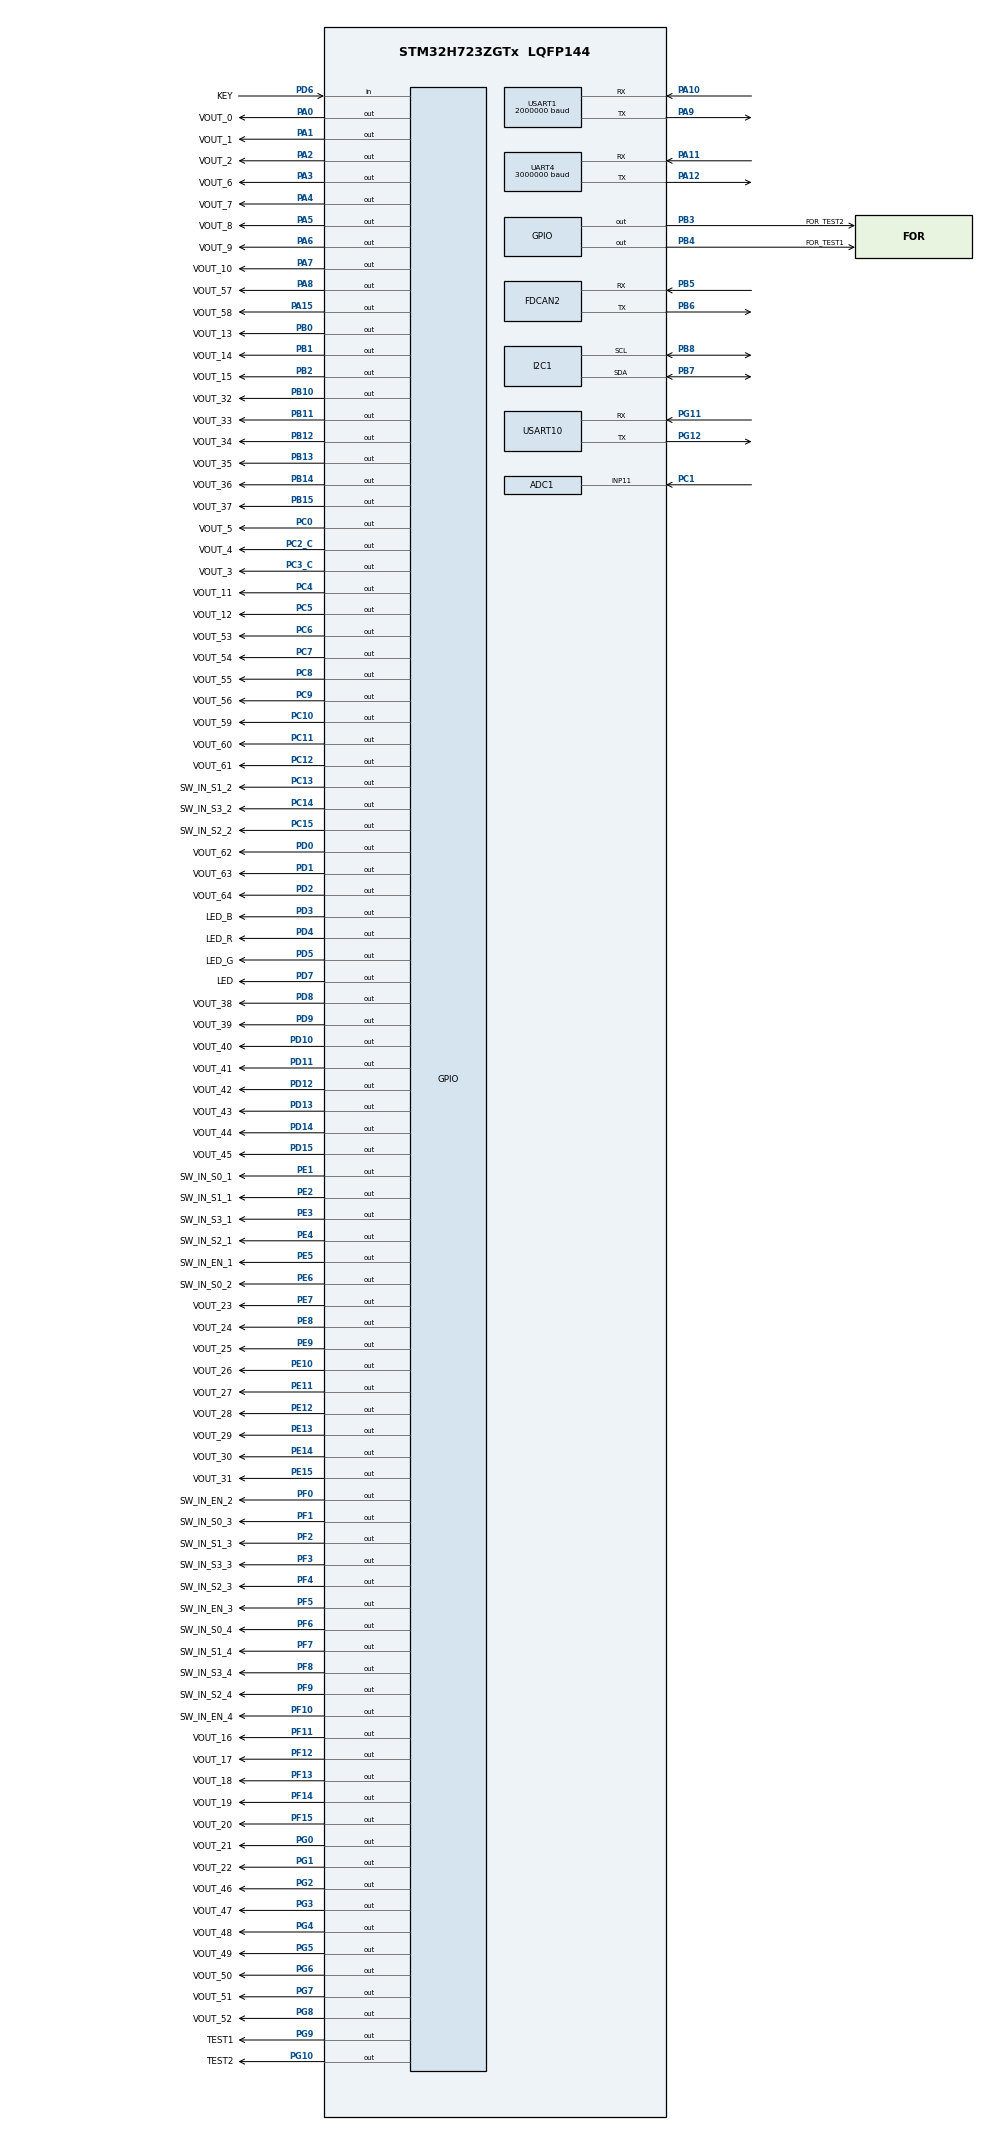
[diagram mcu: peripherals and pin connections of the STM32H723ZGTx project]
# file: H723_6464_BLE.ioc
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ADC1.Channel-0\#ChannelRegularConversion=ADC_CHANNEL_11
ADC1.ContinuousConvMode=ENABLE
ADC1.ConversionDataManagement=ADC_CONVERSIONDATA_DMA_CIRCULAR
ADC1.NbrOfConversionFlag=1
ADC1.OffsetNumber-0\#ChannelRegularConversion=ADC_OFFSET_NONE
ADC1.OffsetSignedSaturation-0\#ChannelRegularConversion=DISABLE
ADC1.Rank-0\#ChannelRegularConversion=1
ADC1.Resolution=ADC_RESOLUTION_10B
ADC1.SamplingTime-0\#ChannelRegularConversion=ADC_SAMPLETIME_1CYCLE_5
ADC1.master=1
CORTEX_M7.AccessPermission_S-Cortex_Memory_Protection_Unit_Region1_Settings_S=MPU_REGION_FULL_ACCESS
CORTEX_M7.BaseAddress_S-Cortex_Memory_Protection_Unit_Region1_Settings_S=0x30000000
CORTEX_M7.CPU_DCache=Enabled
CORTEX_M7.CPU_ICache=Enabled
CORTEX_M7.DisableExec_S-Cortex_Memory_Protection_Unit_Region1_Settings_S=MPU_INSTRUCTION_ACCESS_DISABLE
CORTEX_M7.Enable_S-Cortex_Memory_Protection_Unit_Region1_Settings_S=MPU_REGION_ENABLE
CORTEX_M7.IsBufferable_S-Cortex_Memory_Protection_Unit_Region1_Settings_S=MPU_ACCESS_BUFFERABLE
CORTEX_M7.IsShareable_S-Cortex_Memory_Protection_Unit_Region1_Settings_S=MPU_ACCESS_SHAREABLE
CORTEX_M7.Size_S-Cortex_Memory_Protection_Unit_Region1_Settings_S=MPU_REGION_SIZE_64KB
CORTEX_M7.default_mode_Activation=1
Dma.ADC1.2.Direction=DMA_PERIPH_TO_MEMORY
Dma.ADC1.2.EventEnable=DISABLE
Dma.ADC1.2.FIFOMode=DMA_FIFOMODE_DISABLE
Dma.ADC1.2.Instance=DMA1_Stream2
Dma.ADC1.2.MemDataAlignment=DMA_MDATAALIGN_HALFWORD
Dma.ADC1.2.MemInc=DMA_MINC_ENABLE
Dma.ADC1.2.Mode=DMA_CIRCULAR
Dma.ADC1.2.PeriphDataAlignment=DMA_PDATAALIGN_HALFWORD
Dma.ADC1.2.PeriphInc=DMA_PINC_DISABLE
Dma.ADC1.2.Polarity=HAL_DMAMUX_REQ_GEN_RISING
Dma.ADC1.2.Priority=DMA_PRIORITY_MEDIUM
Dma.ADC1.2.RequestNumber=1
Dma.ADC1.2.SignalID=NONE
Dma.ADC1.2.SyncEnable=DISABLE
Dma.ADC1.2.SyncPolarity=HAL_DMAMUX_SYNC_NO_EVENT
Dma.ADC1.2.SyncRequestNumber=1
Dma.ADC1.2.SyncSignalID=NONE
Dma.Request0=USART1_RX
Dma.Request1=USART1_TX
Dma.Request2=ADC1
Dma.Request3=UART4_TX
Dma.Request4=UART4_RX
Dma.UART4_RX.4.Direction=DMA_PERIPH_TO_MEMORY
Dma.UART4_RX.4.EventEnable=DISABLE
Dma.UART4_RX.4.FIFOMode=DMA_FIFOMODE_DISABLE
Dma.UART4_RX.4.Instance=DMA1_Stream3
Dma.UART4_RX.4.MemDataAlignment=DMA_MDATAALIGN_BYTE
Dma.UART4_RX.4.MemInc=DMA_MINC_ENABLE
Dma.UART4_RX.4.Mode=DMA_NORMAL
Dma.UART4_RX.4.PeriphDataAlignment=DMA_PDATAALIGN_BYTE
Dma.UART4_RX.4.PeriphInc=DMA_PINC_DISABLE
Dma.UART4_RX.4.Polarity=HAL_DMAMUX_REQ_GEN_RISING
Dma.UART4_RX.4.Priority=DMA_PRIORITY_VERY_HIGH
Dma.UART4_RX.4.RequestNumber=1
Dma.UART4_RX.4.SignalID=NONE
Dma.UART4_RX.4.SyncEnable=DISABLE
Dma.UART4_RX.4.SyncPolarity=HAL_DMAMUX_SYNC_NO_EVENT
Dma.UART4_RX.4.SyncRequestNumber=1
Dma.UART4_RX.4.SyncSignalID=NONE
Dma.UART4_TX.3.Direction=DMA_MEMORY_TO_PERIPH
Dma.UART4_TX.3.EventEnable=DISABLE
Dma.UART4_TX.3.FIFOMode=DMA_FIFOMODE_DISABLE
Dma.UART4_TX.3.Instance=DMA1_Stream4
Dma.UART4_TX.3.MemDataAlignment=DMA_MDATAALIGN_BYTE
Dma.UART4_TX.3.MemInc=DMA_MINC_ENABLE
Dma.UART4_TX.3.Mode=DMA_NORMAL
Dma.UART4_TX.3.PeriphDataAlignment=DMA_PDATAALIGN_BYTE
Dma.UART4_TX.3.PeriphInc=DMA_PINC_DISABLE
Dma.UART4_TX.3.Polarity=HAL_DMAMUX_REQ_GEN_RISING
Dma.UART4_TX.3.Priority=DMA_PRIORITY_LOW
Dma.UART4_TX.3.RequestNumber=1
Dma.UART4_TX.3.SignalID=NONE
Dma.UART4_TX.3.SyncEnable=DISABLE
Dma.UART4_TX.3.SyncPolarity=HAL_DMAMUX_SYNC_NO_EVENT
Dma.UART4_TX.3.SyncRequestNumber=1
Dma.UART4_TX.3.SyncSignalID=NONE
Dma.USART1_RX.0.Direction=DMA_PERIPH_TO_MEMORY
Dma.USART1_RX.0.EventEnable=DISABLE
Dma.USART1_RX.0.FIFOMode=DMA_FIFOMODE_DISABLE
Dma.USART1_RX.0.Instance=DMA1_Stream0
Dma.USART1_RX.0.MemDataAlignment=DMA_MDATAALIGN_BYTE
Dma.USART1_RX.0.MemInc=DMA_MINC_ENABLE
Dma.USART1_RX.0.Mode=DMA_NORMAL
Dma.USART1_RX.0.PeriphDataAlignment=DMA_PDATAALIGN_BYTE
Dma.USART1_RX.0.PeriphInc=DMA_PINC_DISABLE
Dma.USART1_RX.0.Polarity=HAL_DMAMUX_REQ_GEN_RISING
Dma.USART1_RX.0.Priority=DMA_PRIORITY_LOW
Dma.USART1_RX.0.RequestNumber=1
Dma.USART1_RX.0.SignalID=NONE
Dma.USART1_RX.0.SyncEnable=DISABLE
Dma.USART1_RX.0.SyncPolarity=HAL_DMAMUX_SYNC_NO_EVENT
Dma.USART1_RX.0.SyncRequestNumber=1
Dma.USART1_RX.0.SyncSignalID=NONE
Dma.USART1_TX.1.Direction=DMA_MEMORY_TO_PERIPH
Dma.USART1_TX.1.EventEnable=DISABLE
Dma.USART1_TX.1.FIFOMode=DMA_FIFOMODE_DISABLE
Dma.USART1_TX.1.Instance=DMA1_Stream1
Dma.USART1_TX.1.MemDataAlignment=DMA_MDATAALIGN_BYTE
Dma.USART1_TX.1.MemInc=DMA_MINC_ENABLE
Dma.USART1_TX.1.Mode=DMA_NORMAL
Dma.USART1_TX.1.PeriphDataAlignment=DMA_PDATAALIGN_BYTE
Dma.USART1_TX.1.PeriphInc=DMA_PINC_DISABLE
Dma.USART1_TX.1.Polarity=HAL_DMAMUX_REQ_GEN_RISING
Dma.USART1_TX.1.Priority=DMA_PRIORITY_LOW
Dma.USART1_TX.1.RequestNumber=1
Dma.USART1_TX.1.SignalID=NONE
Dma.USART1_TX.1.SyncEnable=DISABLE
Dma.USART1_TX.1.SyncPolarity=HAL_DMAMUX_SYNC_NO_EVENT
Dma.USART1_TX.1.SyncRequestNumber=1
Dma.USART1_TX.1.SyncSignalID=NONE
FDCAN2.CalculateBaudRateNominal=2864583
FDCAN2.CalculateTimeBitNominal=349
FDCAN2.CalculateTimeQuantumNominal=116.36363636363636
I2C1.Timing=0x60404E72
Mcu.Family=STM32H7
Mcu.Name=STM32H723ZGTx
Mcu.Package=LQFP144
NVIC.DMA1_Stream0_IRQn=true\:2\:0\:true\:false\:true\:false\:true\:true
NVIC.DMA1_Stream1_IRQn=true\:2\:0\:true\:false\:true\:false\:true\:true
NVIC.DMA1_Stream2_IRQn=true\:1\:0\:true\:false\:true\:false\:true\:true
NVIC.DMA1_Stream3_IRQn=true\:0\:0\:true\:false\:true\:false\:true\:true
NVIC.DMA1_Stream4_IRQn=true\:2\:0\:true\:false\:true\:false\:true\:true
NVIC.PriorityGroup=NVIC_PRIORITYGROUP_4
NVIC.UART4_IRQn=true\:0\:0\:false\:false\:true\:true\:true\:true
NVIC.USART1_IRQn=true\:0\:0\:false\:false\:true\:false\:true\:true
PA0.GPIO_Label=VOUT_0
PA0.GPIO_Speed=GPIO_SPEED_FREQ_VERY_HIGH
PA0.PinState=GPIO_PIN_RESET
PA0.Signal=GPIO_Output
PA1.GPIO_Label=VOUT_1
PA1.GPIO_Speed=GPIO_SPEED_FREQ_VERY_HIGH
PA1.PinState=GPIO_PIN_RESET
PA1.Signal=GPIO_Output
PA10.Mode=Asynchronous
PA10.Signal=USART1_RX
PA11.Mode=Asynchronous
PA11.Signal=UART4_RX
PA12.Mode=Asynchronous
PA12.Signal=UART4_TX
PA13(JTMS/SWDIO).Mode=Serial_Wire
PA13(JTMS/SWDIO).Signal=DEBUG_JTMS-SWDIO
PA14(JTCK/SWCLK).Mode=Serial_Wire
PA14(JTCK/SWCLK).Signal=DEBUG_JTCK-SWCLK
PA15(JTDI).GPIO_Label=VOUT_58
PA15(JTDI).GPIO_Speed=GPIO_SPEED_FREQ_VERY_HIGH
PA15(JTDI).PinState=GPIO_PIN_RESET
PA15(JTDI).Signal=GPIO_Output
PA2.GPIO_Label=VOUT_2
PA2.GPIO_Speed=GPIO_SPEED_FREQ_VERY_HIGH
PA2.PinState=GPIO_PIN_RESET
PA2.Signal=GPIO_Output
PA3.GPIO_Label=VOUT_6
PA3.GPIO_Speed=GPIO_SPEED_FREQ_VERY_HIGH
PA3.PinState=GPIO_PIN_RESET
PA3.Signal=GPIO_Output
PA4.GPIO_Label=VOUT_7
PA4.GPIO_Speed=GPIO_SPEED_FREQ_VERY_HIGH
PA4.PinState=GPIO_PIN_RESET
PA4.Signal=GPIO_Output
PA5.GPIO_Label=VOUT_8
PA5.GPIO_Speed=GPIO_SPEED_FREQ_VERY_HIGH
PA5.PinState=GPIO_PIN_RESET
PA5.Signal=GPIO_Output
PA6.GPIO_Label=VOUT_9
PA6.GPIO_Speed=GPIO_SPEED_FREQ_VERY_HIGH
PA6.PinState=GPIO_PIN_RESET
PA6.Signal=GPIO_Output
PA7.GPIO_Label=VOUT_10
PA7.GPIO_Speed=GPIO_SPEED_FREQ_VERY_HIGH
PA7.PinState=GPIO_PIN_RESET
PA7.Signal=GPIO_Output
PA8.GPIO_Label=VOUT_57
PA8.GPIO_Speed=GPIO_SPEED_FREQ_VERY_HIGH
PA8.PinState=GPIO_PIN_RESET
PA8.Signal=GPIO_Output
PA9.Mode=Asynchronous
PA9.Signal=USART1_TX
PB0.GPIO_Label=VOUT_13
PB0.GPIO_Speed=GPIO_SPEED_FREQ_VERY_HIGH
PB0.PinState=GPIO_PIN_RESET
PB0.Signal=GPIO_Output
PB1.GPIO_Label=VOUT_14
PB1.GPIO_Speed=GPIO_SPEED_FREQ_VERY_HIGH
PB1.PinState=GPIO_PIN_RESET
PB1.Signal=GPIO_Output
PB10.GPIO_Label=VOUT_32
PB10.GPIO_Speed=GPIO_SPEED_FREQ_VERY_HIGH
PB10.PinState=GPIO_PIN_RESET
PB10.Signal=GPIO_Output
PB11.GPIO_Label=VOUT_33
PB11.GPIO_Speed=GPIO_SPEED_FREQ_VERY_HIGH
PB11.PinState=GPIO_PIN_RESET
PB11.Signal=GPIO_Output
PB12.GPIO_Label=VOUT_34
PB12.GPIO_Speed=GPIO_SPEED_FREQ_VERY_HIGH
PB12.PinState=GPIO_PIN_RESET
PB12.Signal=GPIO_Output
PB13.GPIO_Label=VOUT_35
PB13.GPIO_Speed=GPIO_SPEED_FREQ_VERY_HIGH
PB13.PinState=GPIO_PIN_RESET
PB13.Signal=GPIO_Output
PB14.GPIO_Label=VOUT_36
PB14.GPIO_Speed=GPIO_SPEED_FREQ_VERY_HIGH
PB14.PinState=GPIO_PIN_RESET
PB14.Signal=GPIO_Output
PB15.GPIO_Label=VOUT_37
PB15.GPIO_Speed=GPIO_SPEED_FREQ_VERY_HIGH
PB15.PinState=GPIO_PIN_RESET
PB15.Signal=GPIO_Output
PB2.GPIO_Label=VOUT_15
PB2.GPIO_Speed=GPIO_SPEED_FREQ_VERY_HIGH
PB2.PinState=GPIO_PIN_RESET
PB2.Signal=GPIO_Output
PB3(JTDO/TRACESWO).GPIO_Label=FOR_TEST2
PB3(JTDO/TRACESWO).GPIO_Speed=GPIO_SPEED_FREQ_VERY_HIGH
PB3(JTDO/TRACESWO).PinState=GPIO_PIN_SET
PB3(JTDO/TRACESWO).Signal=GPIO_Output
PB4(NJTRST).GPIO_Label=FOR_TEST1
PB4(NJTRST).GPIO_Speed=GPIO_SPEED_FREQ_VERY_HIGH
PB4(NJTRST).PinState=GPIO_PIN_SET
PB4(NJTRST).Signal=GPIO_Output
PB5.Mode=FDCAN_Activate
PB5.Signal=FDCAN2_RX
PB6.Mode=FDCAN_Activate
PB6.Signal=FDCAN2_TX
PB7.Mode=I2C
PB7.Signal=I2C1_SDA
PB8.Mode=I2C
PB8.Signal=I2C1_SCL
PC0.GPIO_Label=VOUT_5
PC0.GPIO_Speed=GPIO_SPEED_FREQ_VERY_HIGH
PC0.PinState=GPIO_PIN_RESET
PC0.Signal=GPIO_Output
PC1.Signal=ADCx_INP11
PC10.GPIO_Label=VOUT_59
PC10.GPIO_Speed=GPIO_SPEED_FREQ_VERY_HIGH
PC10.PinState=GPIO_PIN_RESET
PC10.Signal=GPIO_Output
PC11.GPIO_Label=VOUT_60
PC11.GPIO_Speed=GPIO_SPEED_FREQ_VERY_HIGH
PC11.PinState=GPIO_PIN_RESET
PC11.Signal=GPIO_Output
PC12.GPIO_Label=VOUT_61
PC12.GPIO_Speed=GPIO_SPEED_FREQ_VERY_HIGH
PC12.PinState=GPIO_PIN_RESET
PC12.Signal=GPIO_Output
PC13.GPIO_Label=SW_IN_S1_2
PC13.PinState=GPIO_PIN_RESET
PC13.Signal=GPIO_Output
PC14-OSC32_IN.GPIO_Label=SW_IN_S3_2
PC14-OSC32_IN.PinState=GPIO_PIN_RESET
PC14-OSC32_IN.Signal=GPIO_Output
PC15-OSC32_OUT.GPIO_Label=SW_IN_S2_2
PC15-OSC32_OUT.PinState=GPIO_PIN_RESET
PC15-OSC32_OUT.Signal=GPIO_Output
PC2_C.GPIO_Label=VOUT_4
PC2_C.GPIO_Speed=GPIO_SPEED_FREQ_VERY_HIGH
PC2_C.PinState=GPIO_PIN_RESET
PC2_C.Signal=GPIO_Output
PC3_C.GPIO_Label=VOUT_3
PC3_C.GPIO_Speed=GPIO_SPEED_FREQ_VERY_HIGH
PC3_C.PinState=GPIO_PIN_RESET
PC3_C.Signal=GPIO_Output
PC4.GPIO_Label=VOUT_11
PC4.GPIO_Speed=GPIO_SPEED_FREQ_VERY_HIGH
PC4.PinState=GPIO_PIN_RESET
PC4.Signal=GPIO_Output
PC5.GPIO_Label=VOUT_12
PC5.GPIO_Speed=GPIO_SPEED_FREQ_VERY_HIGH
PC5.PinState=GPIO_PIN_RESET
PC5.Signal=GPIO_Output
PC6.GPIO_Label=VOUT_53
PC6.GPIO_Speed=GPIO_SPEED_FREQ_VERY_HIGH
PC6.PinState=GPIO_PIN_RESET
PC6.Signal=GPIO_Output
PC7.GPIO_Label=VOUT_54
PC7.GPIO_Speed=GPIO_SPEED_FREQ_VERY_HIGH
PC7.PinState=GPIO_PIN_RESET
PC7.Signal=GPIO_Output
PC8.GPIO_Label=VOUT_55
PC8.GPIO_Speed=GPIO_SPEED_FREQ_VERY_HIGH
PC8.PinState=GPIO_PIN_RESET
PC8.Signal=GPIO_Output
PC9.GPIO_Label=VOUT_56
PC9.GPIO_Speed=GPIO_SPEED_FREQ_VERY_HIGH
PC9.PinState=GPIO_PIN_RESET
PC9.Signal=GPIO_Output
PD0.GPIO_Label=VOUT_62
PD0.GPIO_Speed=GPIO_SPEED_FREQ_VERY_HIGH
PD0.PinState=GPIO_PIN_RESET
PD0.Signal=GPIO_Output
PD1.GPIO_Label=VOUT_63
PD1.GPIO_Speed=GPIO_SPEED_FREQ_VERY_HIGH
PD1.PinState=GPIO_PIN_RESET
PD1.Signal=GPIO_Output
PD10.GPIO_Label=VOUT_40
PD10.GPIO_Speed=GPIO_SPEED_FREQ_VERY_HIGH
PD10.PinState=GPIO_PIN_RESET
PD10.Signal=GPIO_Output
PD11.GPIO_Label=VOUT_41
PD11.GPIO_Speed=GPIO_SPEED_FREQ_VERY_HIGH
PD11.PinState=GPIO_PIN_RESET
PD11.Signal=GPIO_Output
PD12.GPIO_Label=VOUT_42
PD12.GPIO_Speed=GPIO_SPEED_FREQ_VERY_HIGH
PD12.PinState=GPIO_PIN_RESET
PD12.Signal=GPIO_Output
PD13.GPIO_Label=VOUT_43
PD13.GPIO_Speed=GPIO_SPEED_FREQ_VERY_HIGH
PD13.PinState=GPIO_PIN_RESET
PD13.Signal=GPIO_Output
PD14.GPIO_Label=VOUT_44
PD14.GPIO_Speed=GPIO_SPEED_FREQ_VERY_HIGH
PD14.PinState=GPIO_PIN_RESET
PD14.Signal=GPIO_Output
PD15.GPIO_Label=VOUT_45
PD15.GPIO_Speed=GPIO_SPEED_FREQ_VERY_HIGH
PD15.PinState=GPIO_PIN_RESET
PD15.Signal=GPIO_Output
PD2.GPIO_Label=VOUT_64
PD2.GPIO_Speed=GPIO_SPEED_FREQ_VERY_HIGH
PD2.PinState=GPIO_PIN_RESET
PD2.Signal=GPIO_Output
PD3.GPIO_Label=LED_B
PD3.GPIO_Speed=GPIO_SPEED_FREQ_VERY_HIGH
PD3.PinState=GPIO_PIN_SET
PD3.Signal=GPIO_Output
PD4.GPIO_Label=LED_R
PD4.GPIO_Speed=GPIO_SPEED_FREQ_VERY_HIGH
PD4.PinState=GPIO_PIN_SET
PD4.Signal=GPIO_Output
PD5.GPIO_Label=LED_G
PD5.GPIO_Speed=GPIO_SPEED_FREQ_VERY_HIGH
PD5.PinState=GPIO_PIN_SET
PD5.Signal=GPIO_Output
PD6.GPIO_Label=KEY
PD6.Signal=GPIO_Input
PD7.GPIO_Label=LED
PD7.GPIO_Speed=GPIO_SPEED_FREQ_VERY_HIGH
PD7.PinState=GPIO_PIN_SET
PD7.Signal=GPIO_Output
PD8.GPIO_Label=VOUT_38
PD8.GPIO_Speed=GPIO_SPEED_FREQ_VERY_HIGH
PD8.PinState=GPIO_PIN_RESET
PD8.Signal=GPIO_Output
PD9.GPIO_Label=VOUT_39
PD9.GPIO_Speed=GPIO_SPEED_FREQ_VERY_HIGH
PD9.PinState=GPIO_PIN_RESET
PD9.Signal=GPIO_Output
PE1.GPIO_Label=SW_IN_S0_1
PE1.GPIO_Speed=GPIO_SPEED_FREQ_VERY_HIGH
PE1.PinState=GPIO_PIN_RESET
PE1.Signal=GPIO_Output
PE10.GPIO_Label=VOUT_26
PE10.GPIO_Speed=GPIO_SPEED_FREQ_VERY_HIGH
PE10.PinState=GPIO_PIN_RESET
PE10.Signal=GPIO_Output
PE11.GPIO_Label=VOUT_27
PE11.GPIO_Speed=GPIO_SPEED_FREQ_VERY_HIGH
PE11.PinState=GPIO_PIN_RESET
PE11.Signal=GPIO_Output
PE12.GPIO_Label=VOUT_28
PE12.GPIO_Speed=GPIO_SPEED_FREQ_VERY_HIGH
PE12.PinState=GPIO_PIN_RESET
PE12.Signal=GPIO_Output
PE13.GPIO_Label=VOUT_29
PE13.GPIO_Speed=GPIO_SPEED_FREQ_VERY_HIGH
PE13.PinState=GPIO_PIN_RESET
PE13.Signal=GPIO_Output
PE14.GPIO_Label=VOUT_30
PE14.GPIO_Speed=GPIO_SPEED_FREQ_VERY_HIGH
PE14.PinState=GPIO_PIN_RESET
PE14.Signal=GPIO_Output
PE15.GPIO_Label=VOUT_31
PE15.GPIO_Speed=GPIO_SPEED_FREQ_VERY_HIGH
PE15.PinState=GPIO_PIN_RESET
PE15.Signal=GPIO_Output
PE2.GPIO_Label=SW_IN_S1_1
PE2.GPIO_Speed=GPIO_SPEED_FREQ_VERY_HIGH
PE2.PinState=GPIO_PIN_RESET
PE2.Signal=GPIO_Output
PE3.GPIO_Label=SW_IN_S3_1
PE3.GPIO_Speed=GPIO_SPEED_FREQ_VERY_HIGH
PE3.PinState=GPIO_PIN_RESET
PE3.Signal=GPIO_Output
PE4.GPIO_Label=SW_IN_S2_1
PE4.GPIO_Speed=GPIO_SPEED_FREQ_VERY_HIGH
PE4.PinState=GPIO_PIN_RESET
PE4.Signal=GPIO_Output
PE5.GPIO_Label=SW_IN_EN_1
PE5.GPIO_Speed=GPIO_SPEED_FREQ_VERY_HIGH
PE5.PinState=GPIO_PIN_SET
PE5.Signal=GPIO_Output
PE6.GPIO_Label=SW_IN_S0_2
PE6.GPIO_Speed=GPIO_SPEED_FREQ_VERY_HIGH
PE6.PinState=GPIO_PIN_RESET
PE6.Signal=GPIO_Output
PE7.GPIO_Label=VOUT_23
PE7.GPIO_Speed=GPIO_SPEED_FREQ_VERY_HIGH
PE7.PinState=GPIO_PIN_RESET
PE7.Signal=GPIO_Output
PE8.GPIO_Label=VOUT_24
PE8.GPIO_Speed=GPIO_SPEED_FREQ_VERY_HIGH
PE8.PinState=GPIO_PIN_RESET
PE8.Signal=GPIO_Output
PE9.GPIO_Label=VOUT_25
PE9.GPIO_Speed=GPIO_SPEED_FREQ_VERY_HIGH
PE9.PinState=GPIO_PIN_RESET
PE9.Signal=GPIO_Output
PF0.GPIO_Label=SW_IN_EN_2
PF0.GPIO_Speed=GPIO_SPEED_FREQ_VERY_HIGH
PF0.PinState=GPIO_PIN_SET
PF0.Signal=GPIO_Output
PF1.GPIO_Label=SW_IN_S0_3
PF1.GPIO_Speed=GPIO_SPEED_FREQ_VERY_HIGH
PF1.PinState=GPIO_PIN_RESET
PF1.Signal=GPIO_Output
PF10.GPIO_Label=SW_IN_EN_4
PF10.GPIO_Speed=GPIO_SPEED_FREQ_VERY_HIGH
PF10.PinState=GPIO_PIN_SET
PF10.Signal=GPIO_Output
PF11.GPIO_Label=VOUT_16
PF11.GPIO_Speed=GPIO_SPEED_FREQ_VERY_HIGH
PF11.PinState=GPIO_PIN_RESET
PF11.Signal=GPIO_Output
PF12.GPIO_Label=VOUT_17
PF12.GPIO_Speed=GPIO_SPEED_FREQ_VERY_HIGH
PF12.PinState=GPIO_PIN_RESET
PF12.Signal=GPIO_Output
PF13.GPIO_Label=VOUT_18
PF13.GPIO_Speed=GPIO_SPEED_FREQ_VERY_HIGH
PF13.PinState=GPIO_PIN_RESET
PF13.Signal=GPIO_Output
PF14.GPIO_Label=VOUT_19
PF14.GPIO_Speed=GPIO_SPEED_FREQ_VERY_HIGH
PF14.PinState=GPIO_PIN_RESET
PF14.Signal=GPIO_Output
PF15.GPIO_Label=VOUT_20
PF15.GPIO_Speed=GPIO_SPEED_FREQ_VERY_HIGH
PF15.PinState=GPIO_PIN_RESET
PF15.Signal=GPIO_Output
PF2.GPIO_Label=SW_IN_S1_3
PF2.GPIO_Speed=GPIO_SPEED_FREQ_VERY_HIGH
PF2.PinState=GPIO_PIN_RESET
PF2.Signal=GPIO_Output
PF3.GPIO_Label=SW_IN_S3_3
PF3.GPIO_Speed=GPIO_SPEED_FREQ_VERY_HIGH
PF3.PinState=GPIO_PIN_RESET
PF3.Signal=GPIO_Output
PF4.GPIO_Label=SW_IN_S2_3
PF4.GPIO_Speed=GPIO_SPEED_FREQ_VERY_HIGH
PF4.PinState=GPIO_PIN_RESET
PF4.Signal=GPIO_Output
PF5.GPIO_Label=SW_IN_EN_3
PF5.GPIO_Speed=GPIO_SPEED_FREQ_VERY_HIGH
PF5.PinState=GPIO_PIN_SET
PF5.Signal=GPIO_Output
PF6.GPIO_Label=SW_IN_S0_4
PF6.GPIO_Speed=GPIO_SPEED_FREQ_VERY_HIGH
PF6.PinState=GPIO_PIN_RESET
PF6.Signal=GPIO_Output
PF7.GPIO_Label=SW_IN_S1_4
PF7.GPIO_Speed=GPIO_SPEED_FREQ_VERY_HIGH
PF7.PinState=GPIO_PIN_RESET
PF7.Signal=GPIO_Output
PF8.GPIO_Label=SW_IN_S3_4
PF8.GPIO_Speed=GPIO_SPEED_FREQ_VERY_HIGH
PF8.PinState=GPIO_PIN_RESET
PF8.Signal=GPIO_Output
PF9.GPIO_Label=SW_IN_S2_4
PF9.GPIO_Speed=GPIO_SPEED_FREQ_VERY_HIGH
PF9.PinState=GPIO_PIN_RESET
PF9.Signal=GPIO_Output
PG0.GPIO_Label=VOUT_21
PG0.GPIO_Speed=GPIO_SPEED_FREQ_VERY_HIGH
PG0.PinState=GPIO_PIN_RESET
PG0.Signal=GPIO_Output
PG1.GPIO_Label=VOUT_22
PG1.GPIO_Speed=GPIO_SPEED_FREQ_VERY_HIGH
PG1.PinState=GPIO_PIN_RESET
PG1.Signal=GPIO_Output
PG10.GPIO_Label=TEST2
PG10.GPIO_Speed=GPIO_SPEED_FREQ_VERY_HIGH
PG10.Signal=GPIO_Output
PG11.Mode=Asynchronous
PG11.Signal=USART10_RX
PG12.Mode=Asynchronous
PG12.Signal=USART10_TX
PG2.GPIO_Label=VOUT_46
PG2.GPIO_Speed=GPIO_SPEED_FREQ_VERY_HIGH
PG2.PinState=GPIO_PIN_RESET
PG2.Signal=GPIO_Output
PG3.GPIO_Label=VOUT_47
PG3.GPIO_Speed=GPIO_SPEED_FREQ_VERY_HIGH
PG3.PinState=GPIO_PIN_RESET
PG3.Signal=GPIO_Output
PG4.GPIO_Label=VOUT_48
PG4.GPIO_Speed=GPIO_SPEED_FREQ_VERY_HIGH
PG4.PinState=GPIO_PIN_RESET
PG4.Signal=GPIO_Output
PG5.GPIO_Label=VOUT_49
PG5.GPIO_Speed=GPIO_SPEED_FREQ_VERY_HIGH
PG5.PinState=GPIO_PIN_RESET
PG5.Signal=GPIO_Output
PG6.GPIO_Label=VOUT_50
PG6.GPIO_Speed=GPIO_SPEED_FREQ_VERY_HIGH
PG6.PinState=GPIO_PIN_RESET
PG6.Signal=GPIO_Output
PG7.GPIO_Label=VOUT_51
PG7.GPIO_Speed=GPIO_SPEED_FREQ_VERY_HIGH
PG7.PinState=GPIO_PIN_RESET
PG7.Signal=GPIO_Output
PG8.GPIO_Label=VOUT_52
PG8.GPIO_Speed=GPIO_SPEED_FREQ_VERY_HIGH
PG8.PinState=GPIO_PIN_RESET
PG8.Signal=GPIO_Output
PG9.GPIO_Label=TEST1
PG9.GPIO_Speed=GPIO_SPEED_FREQ_VERY_HIGH
PG9.Signal=GPIO_Output
PH0-OSC_IN.Mode=HSE-External-Oscillator
PH0-OSC_IN.Signal=RCC_OSC_IN
PH1-OSC_OUT.Mode=HSE-External-Oscillator
PH1-OSC_OUT.Signal=RCC_OSC_OUT
ProjectManager.HeapSize=0x200
ProjectManager.StackSize=0x400
ProjectManager.TargetToolchain=MDK-ARM V5.32
RCC.ADCFreq_Value=96000000
RCC.APB1Freq_Value=137500000
RCC.APB2Freq_Value=137500000
RCC.APB3Freq_Value=137500000
RCC.APB4Freq_Value=137500000
RCC.CortexFreq_Value=550000000
RCC.D1PPRE=RCC_APB3_DIV2
RCC.D2PPRE1=RCC_APB1_DIV2
RCC.D2PPRE2=RCC_APB2_DIV2
RCC.D3PPRE=RCC_APB4_DIV2
RCC.DIVM1=4
RCC.DIVM2=4
RCC.DIVN1=34
RCC.DIVN2=12
RCC.DIVP1=1
RCC.DIVQ1=4
RCC.HCLKFreq_Value=275000000
RCC.HPRE=RCC_HCLK_DIV2
RCC.PLL2FRACN=0
RCC.PLL3FRACN=0
RCC.PLLFRACN=3072
RCC.SYSCLKFreq_VALUE=550000000
RCC.SYSCLKSource=RCC_SYSCLKSOURCE_PLLCLK
RCC.USBFreq_Value=137500000
SH.ADCx_INP11.0=ADC1_INP11,IN11-Single-Ended
UART4.BaudRate=3000000
USART1.BaudRate=2000000
USART1.VirtualMode-Asynchronous=VM_ASYNC
USART10.VirtualMode-Asynchronous=VM_ASYNC
VP_MEMORYMAP_VS_MEMORYMAP.Mode=CurAppReg
board=custom

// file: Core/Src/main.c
/* USER CODE BEGIN Header */
/**
 ******************************************************************************
 * @file           : main.c
 * @brief          : Main program body
 ******************************************************************************
 * @attention
 *
 * Copyright (c) 2025 STMicroelectronics.
 * All rights reserved.
 *
 * This software is licensed under terms that can be found in the LICENSE file
 * in the root directory of this software component.
 * If no LICENSE file comes with this software, it is provided AS-IS.
 *
 ******************************************************************************
 */
/* USER CODE END Header */
#include "main.h"
#include "adc.h"
#include "dma.h"
#include "fdcan.h"
#include "i2c.h"
#include "usart.h"
#include "gpio.h"

/* USER CODE BEGIN Includes */
#include "user_comm.h"

/* USER CODE END Includes */

void SystemClock_Config(void);
static void MPU_Config(void);

int main(void)
{

    /* USER CODE BEGIN 1 */
    SCB_EnableICache(); // Enable instruction cache
    SCB_EnableDCache(); // Enable data cache
    /* USER CODE END 1 */

    /* MPU Configuration--------------------------------------------------------*/
    MPU_Config();

    /* Enable the CPU Cache */

    /* Enable I-Cache---------------------------------------------------------*/
    SCB_EnableICache();

    /* Enable D-Cache---------------------------------------------------------*/
    SCB_EnableDCache();

    /* MCU Configuration--------------------------------------------------------*/

    /* Reset of all peripherals, Initializes the Flash interface and the Systick. */
    HAL_Init();

    /* Configure the system clock */
    SystemClock_Config();

    /* Initialize all configured peripherals */
    MX_GPIO_Init();
    MX_DMA_Init();
    MX_ADC1_Init();
    MX_USART1_UART_Init();
    MX_FDCAN2_Init();
    MX_I2C1_Init();
    MX_USART10_UART_Init();
    MX_UART4_Init();
    /* USER CODE BEGIN 2 */

    HAL_GPIO_WritePin(LED_B_GPIO_Port, LED_B_Pin, GPIO_PIN_RESET);

    delay_init(SystemCoreClock / 1000000);

    init_frame_tail();

    start_uart_rx();

    start_adc_dma();

    // 点亮GLED
    // HAL_GPIO_WritePin(LED_G_GPIO_Port, LED_G_Pin, GPIO_PIN_RESET);
    /* USER CODE END 2 */

    /* Infinite loop */
    /* USER CODE BEGIN WHILE */

    while (1)
    {

        // comm_handler();
        // led_task();
        main_task_adc_first();

        // test_task();

        // uart_test();
        /* USER CODE END WHILE */

    }
}

void SystemClock_Config(void)
{
    RCC_OscInitTypeDef RCC_OscInitStruct = {0};
    RCC_ClkInitTypeDef RCC_ClkInitStruct = {0};

    /** Supply configuration update enable
     */
    HAL_PWREx_ConfigSupply(PWR_LDO_SUPPLY);

    /** Configure the main internal regulator output voltage
     */
    __HAL_PWR_VOLTAGESCALING_CONFIG(PWR_REGULATOR_VOLTAGE_SCALE0);

    while (!__HAL_PWR_GET_FLAG(PWR_FLAG_VOSRDY))
    {
    }

    /** Initializes the RCC Oscillators according to the specified parameters
     * in the RCC_OscInitTypeDef structure.
     */
    RCC_OscInitStruct.OscillatorType = RCC_OSCILLATORTYPE_HSI;
    RCC_OscInitStruct.HSIState = RCC_HSI_DIV1;
    RCC_OscInitStruct.HSICalibrationValue = 64;
    RCC_OscInitStruct.PLL.PLLState = RCC_PLL_ON;
    RCC_OscInitStruct.PLL.PLLSource = RCC_PLLSOURCE_HSI;
    RCC_OscInitStruct.PLL.PLLM = 4;
    RCC_OscInitStruct.PLL.PLLN = 34;
    RCC_OscInitStruct.PLL.PLLP = 1;
    RCC_OscInitStruct.PLL.PLLQ = 4;
    RCC_OscInitStruct.PLL.PLLR = 2;
    RCC_OscInitStruct.PLL.PLLRGE = RCC_PLL1VCIRANGE_3;
    RCC_OscInitStruct.PLL.PLLVCOSEL = RCC_PLL1VCOWIDE;
    RCC_OscInitStruct.PLL.PLLFRACN = 3072;
    if (HAL_RCC_OscConfig(&RCC_OscInitStruct) != HAL_OK)
    {
        Error_Handler();
    }

    /** Initializes the CPU, AHB and APB buses clocks
     */
    RCC_ClkInitStruct.ClockType = RCC_CLOCKTYPE_HCLK | RCC_CLOCKTYPE_SYSCLK | RCC_CLOCKTYPE_PCLK1 | RCC_CLOCKTYPE_PCLK2 | RCC_CLOCKTYPE_D3PCLK1 | RCC_CLOCKTYPE_D1PCLK1;
    RCC_ClkInitStruct.SYSCLKSource = RCC_SYSCLKSOURCE_PLLCLK;
    RCC_ClkInitStruct.SYSCLKDivider = RCC_SYSCLK_DIV1;
    RCC_ClkInitStruct.AHBCLKDivider = RCC_HCLK_DIV2;
    RCC_ClkInitStruct.APB3CLKDivider = RCC_APB3_DIV2;
    RCC_ClkInitStruct.APB1CLKDivider = RCC_APB1_DIV2;
    RCC_ClkInitStruct.APB2CLKDivider = RCC_APB2_DIV2;
    RCC_ClkInitStruct.APB4CLKDivider = RCC_APB4_DIV2;

    if (HAL_RCC_ClockConfig(&RCC_ClkInitStruct, FLASH_LATENCY_3) != HAL_OK)
    {
        Error_Handler();
    }
}

/* MPU Configuration */

void MPU_Config(void)
{
    MPU_Region_InitTypeDef MPU_InitStruct = {0};

    /* Disables the MPU */
    HAL_MPU_Disable();

    /** Initializes and configures the Region and the memory to be protected
     */
    MPU_InitStruct.Enable = MPU_REGION_ENABLE;
    MPU_InitStruct.Number = MPU_REGION_NUMBER0;
    MPU_InitStruct.BaseAddress = 0x0;
    MPU_InitStruct.Size = MPU_REGION_SIZE_4GB;
    MPU_InitStruct.SubRegionDisable = 0x87;
    MPU_InitStruct.TypeExtField = MPU_TEX_LEVEL0;
    MPU_InitStruct.AccessPermission = MPU_REGION_NO_ACCESS;
    MPU_InitStruct.DisableExec = MPU_INSTRUCTION_ACCESS_DISABLE;
    MPU_InitStruct.IsShareable = MPU_ACCESS_SHAREABLE;
    MPU_InitStruct.IsCacheable = MPU_ACCESS_NOT_CACHEABLE;
    MPU_InitStruct.IsBufferable = MPU_ACCESS_NOT_BUFFERABLE;

    HAL_MPU_ConfigRegion(&MPU_InitStruct);

    /** Initializes and configures the Region and the memory to be protected
     */
    MPU_InitStruct.Number = MPU_REGION_NUMBER1;
    MPU_InitStruct.BaseAddress = 0x30000000;
    MPU_InitStruct.Size = MPU_REGION_SIZE_64KB;
    MPU_InitStruct.SubRegionDisable = 0x0;
    MPU_InitStruct.AccessPermission = MPU_REGION_FULL_ACCESS;
    MPU_InitStruct.IsBufferable = MPU_ACCESS_BUFFERABLE;

    HAL_MPU_ConfigRegion(&MPU_InitStruct);
    /* Enables the MPU */
    HAL_MPU_Enable(MPU_PRIVILEGED_DEFAULT);
}

void Error_Handler(void)
{
    __disable_irq();
    while (1)
    {
    }
}
